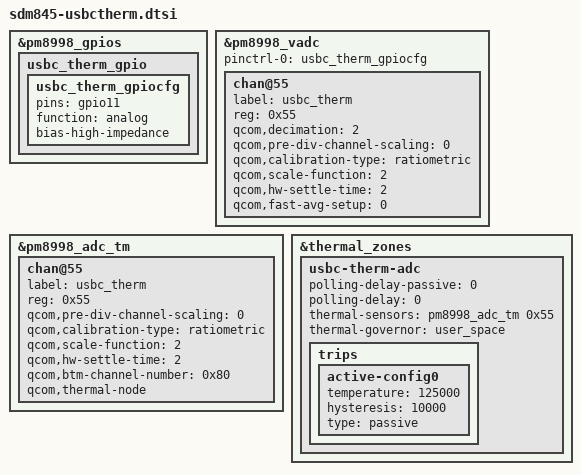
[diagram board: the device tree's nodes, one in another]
&pm8998_gpios {
	usbc_therm_gpio {
		usbc_therm_gpiocfg: usbc_therm_gpiocfg {
			pins = "gpio11";
			function="analog";
			bias-high-impedance;
		};
	};
};

&pm8998_vadc {
    pinctrl-names = "default";
    pinctrl-0 = <&usbc_therm_gpiocfg>;

	/* This node can't be disabled w/ status = "disable" */
	chan@55 {
		label = "usbc_therm";
		reg = <0x55>;
		qcom,decimation = <2>;
		qcom,pre-div-channel-scaling = <0>;
		qcom,calibration-type = "ratiometric";
		qcom,scale-function = <2>;
		qcom,hw-settle-time = <2>;
		qcom,fast-avg-setup = <0>;
	};
};

&pm8998_adc_tm {
	chan@55 {
		label = "usbc_therm";
		reg = <0x55>;
		qcom,pre-div-channel-scaling = <0>;
		qcom,calibration-type = "ratiometric";
		qcom,scale-function = <2>;
		qcom,hw-settle-time = <2>;
		qcom,btm-channel-number = <0x80>;
		qcom,thermal-node;
	};
};

&thermal_zones {
	usbc-therm-adc {
		polling-delay-passive = <0>;
		polling-delay = <0>;
		thermal-sensors = <&pm8998_adc_tm 0x55>;
		thermal-governor = "user_space";

		trips {
			active-config0 {
				temperature = <125000>;
				hysteresis = <10000>;
				type = "passive";
			};
		};
	};
};
